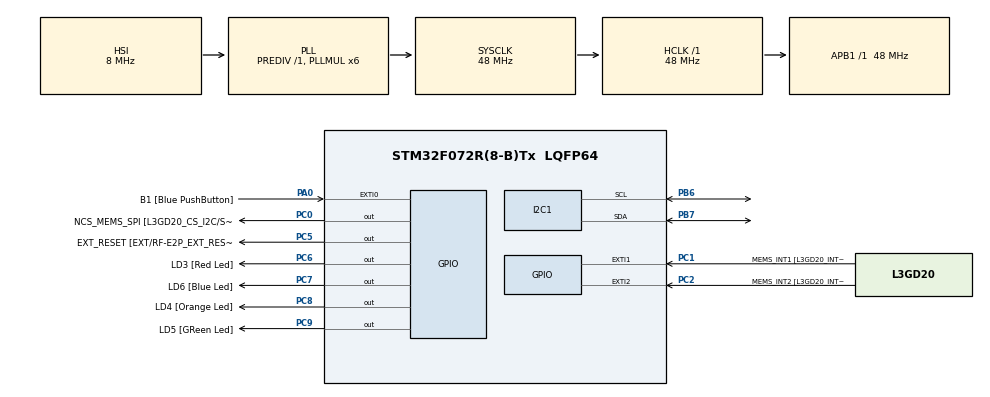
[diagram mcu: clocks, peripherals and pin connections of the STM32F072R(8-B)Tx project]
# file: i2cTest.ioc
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I2C1.Speed=100
I2C1.Timing=0x2000090E
Mcu.Family=STM32F0
Mcu.Name=STM32F072R(8-B)Tx
Mcu.Package=LQFP64
NVIC.TIM3_IRQn=true\:0\:0\:false\:false\:true
PA0.GPIO_Label=B1 [Blue PushButton]
PA0.GPIO_ModeDefaultEXTI=GPIO_MODE_EVT_RISING
PA0.Signal=GPXTI0
PA11.GPIO_Label=USBF4_DM
PA11.Signal=USB_DM
PA12.GPIO_Label=USBF4_DP
PA12.Signal=USB_DP
PA13.GPIO_Label=SWDIO
PA13.Signal=SYS_SWDIO
PA14.GPIO_Label=SWCLK
PA14.Signal=SYS_SWCLK
PA2.Signal=TSC_G1_IO3
PA3.Signal=TSC_G1_IO4
PA6.Signal=TSC_G2_IO3
PA7.Signal=TSC_G2_IO4
PB0.Signal=TSC_G3_IO2
PB1.Signal=TSC_G3_IO3
PB10.GPIO_Label=I2C2_SCL[EXT/RF-E2P_SCL]
PB10.Signal=I2C2_SCL
PB11.GPIO_Label=I2C2_SDA[EXT/RF-E2P_SDA]
PB11.Signal=I2C2_SDA
PB13.GPIO_Label=SPI2_SCK [L3GD20_SCL/SPC]
PB13.Signal=SPI2_SCK
PB14.GPIO_Label=SPI2_MISO [L3GD20_SDO]
PB14.Signal=SPI2_MISO
PB15.GPIO_Label=SPI2_MOSI [L3GD20_SDA/SDI]
PB15.Signal=SPI2_MOSI
PB6.Mode=I2C
PB6.Signal=I2C1_SCL
PB7.Mode=I2C
PB7.Signal=I2C1_SDA
PC0.GPIO_Label=NCS_MEMS_SPI [L3GD20_CS_I2C/SPI]
PC0.Signal=GPIO_Output
PC1.GPIO_Label=MEMS_INT1 [L3GD20_INT1]
PC1.GPIO_ModeDefaultEXTI=GPIO_MODE_EVT_RISING
PC1.Signal=GPXTI1
PC2.GPIO_Label=MEMS_INT2 [L3GD20_INT2]
PC2.GPIO_ModeDefaultEXTI=GPIO_MODE_EVT_RISING
PC2.Signal=GPXTI2
PC5.GPIO_Label=EXT_RESET [EXT/RF-E2P_EXT_RESET]
PC5.Signal=GPIO_Output
PC6.GPIO_Label=LD3 [Red Led]
PC6.Signal=GPIO_Output
PC7.GPIO_Label=LD6 [Blue Led]
PC7.Signal=GPIO_Output
PC8.GPIO_Label=LD4 [Orange Led]
PC8.Signal=GPIO_Output
PC9.GPIO_Label=LD5 [GReen Led]
PC9.Signal=GPIO_Output
ProjectManager.HeapSize=0x200
ProjectManager.StackSize=0x400
ProjectManager.TargetToolchain=SW4STM32
RCC.AHBFreq_Value=48000000
RCC.APB1Freq_Value=48000000
RCC.APB1TimFreq_Value=48000000
RCC.HCLKFreq_Value=48000000
RCC.PLLMUL=RCC_PLL_MUL6
RCC.SYSCLKFreq_VALUE=48000000
RCC.SYSCLKSource=RCC_SYSCLKSOURCE_PLLCLK
TIM3.Period=499
TIM3.Prescaler=48000
VP_TIM3_VS_ClockSourceINT.Mode=Internal
board=STM32F072B-DISCO

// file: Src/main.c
/**
  ******************************************************************************
  * File Name          : main.c
  * Description        : Main program body
  ******************************************************************************
  *
  * COPYRIGHT(c) 2016 STMicroelectronics
  *
  * Redistribution and use in source and binary forms, with or without modification,
  * are permitted provided that the following conditions are met:
  *   1. Redistributions of source code must retain the above copyright notice,
  *      this list of conditions and the following disclaimer.
  *   2. Redistributions in binary form must reproduce the above copyright notice,
  *      this list of conditions and the following disclaimer in the documentation
  *      and/or other materials provided with the distribution.
  *   3. Neither the name of STMicroelectronics nor the names of its contributors
  *      may be used to endorse or promote products derived from this software
  *      without specific prior written permission.
  *
  * THIS SOFTWARE IS PROVIDED BY THE COPYRIGHT HOLDERS AND CONTRIBUTORS "AS IS"
  * AND ANY EXPRESS OR IMPLIED WARRANTIES, INCLUDING, BUT NOT LIMITED TO, THE
  * IMPLIED WARRANTIES OF MERCHANTABILITY AND FITNESS FOR A PARTICULAR PURPOSE ARE
  * DISCLAIMED. IN NO EVENT SHALL THE COPYRIGHT HOLDER OR CONTRIBUTORS BE LIABLE
  * FOR ANY DIRECT, INDIRECT, INCIDENTAL, SPECIAL, EXEMPLARY, OR CONSEQUENTIAL
  * DAMAGES (INCLUDING, BUT NOT LIMITED TO, PROCUREMENT OF SUBSTITUTE GOODS OR
  * SERVICES; LOSS OF USE, DATA, OR PROFITS; OR BUSINESS INTERRUPTION) HOWEVER
  * CAUSED AND ON ANY THEORY OF LIABILITY, WHETHER IN CONTRACT, STRICT LIABILITY,
  * OR TORT (INCLUDING NEGLIGENCE OR OTHERWISE) ARISING IN ANY WAY OUT OF THE USE
  * OF THIS SOFTWARE, EVEN IF ADVISED OF THE POSSIBILITY OF SUCH DAMAGE.
  *
  ******************************************************************************
  */
#include "stm32f0xx_hal.h"
#include <stdio.h>
#include <stdlib.h>
//http://www.openstm32.org/tiki-view_forum_thread.php?comments_parentId=1904&forumId=7

I2C_HandleTypeDef hi2c1;

TIM_HandleTypeDef htim3;

/* USER CODE BEGIN PV */
/* Private variables ---------------------------------------------------------*/

/* USER CODE END PV */

void SystemClock_Config(void);
void Error_Handler(void);
static void MX_GPIO_Init(void);
static void MX_I2C1_Init(void);
static void MX_TIM3_Init(void);
/* USER CODE BEGIN PFP */
/* Private function prototypes -----------------------------------------------*/

/* USER CODE END PFP */

int main(void)
{

  /* USER CODE BEGIN 1 */

	I2C_GenerateSTART();
  /* USER CODE END 1 */

  /* MCU Configuration----------------------------------------------------------*/

  /* Reset of all peripherals, Initializes the Flash interface and the Systick. */
  HAL_Init();

  /* Configure the system clock */
  SystemClock_Config();

  /* Initialize all configured peripherals */
  MX_GPIO_Init();
  MX_I2C1_Init();
  MX_TIM3_Init();

  /* Infinite loop */
  /* USER CODE BEGIN WHILE */
  initialise_monitor_handles();

  printf("Hello !\n");
  int count;
  //setbuf(stdout,NULL);
  while (1)
  {
	  HAL_Delay(10000); //stop for 10sec
	  printf("intest\n");

  /* USER CODE END WHILE */

  }

}

/** System Clock Configuration
*/
void SystemClock_Config(void)
{

  RCC_OscInitTypeDef RCC_OscInitStruct;
  RCC_ClkInitTypeDef RCC_ClkInitStruct;
  RCC_PeriphCLKInitTypeDef PeriphClkInit;

  RCC_OscInitStruct.OscillatorType = RCC_OSCILLATORTYPE_HSI;
  RCC_OscInitStruct.HSIState = RCC_HSI_ON;
  RCC_OscInitStruct.HSICalibrationValue = 16;
  RCC_OscInitStruct.PLL.PLLState = RCC_PLL_ON;
  RCC_OscInitStruct.PLL.PLLSource = RCC_PLLSOURCE_HSI;
  RCC_OscInitStruct.PLL.PLLMUL = RCC_PLL_MUL6;
  RCC_OscInitStruct.PLL.PREDIV = RCC_PREDIV_DIV1;
  if (HAL_RCC_OscConfig(&RCC_OscInitStruct) != HAL_OK)
  {
    Error_Handler();
  }

  RCC_ClkInitStruct.ClockType = RCC_CLOCKTYPE_HCLK|RCC_CLOCKTYPE_SYSCLK
                              |RCC_CLOCKTYPE_PCLK1;
  RCC_ClkInitStruct.SYSCLKSource = RCC_SYSCLKSOURCE_PLLCLK;
  RCC_ClkInitStruct.AHBCLKDivider = RCC_SYSCLK_DIV1;
  RCC_ClkInitStruct.APB1CLKDivider = RCC_HCLK_DIV1;
  if (HAL_RCC_ClockConfig(&RCC_ClkInitStruct, FLASH_LATENCY_1) != HAL_OK)
  {
    Error_Handler();
  }

  PeriphClkInit.PeriphClockSelection = RCC_PERIPHCLK_I2C1;
  PeriphClkInit.I2c1ClockSelection = RCC_I2C1CLKSOURCE_HSI;
  if (HAL_RCCEx_PeriphCLKConfig(&PeriphClkInit) != HAL_OK)
  {
    Error_Handler();
  }

  HAL_SYSTICK_Config(HAL_RCC_GetHCLKFreq()/1000);

  HAL_SYSTICK_CLKSourceConfig(SYSTICK_CLKSOURCE_HCLK);

  /* SysTick_IRQn interrupt configuration */
  HAL_NVIC_SetPriority(SysTick_IRQn, 0, 0);
}

/* I2C1 init function */
static void MX_I2C1_Init(void)
{

  hi2c1.Instance = I2C1;
  hi2c1.Init.Timing = 0x2000090E;
  hi2c1.Init.OwnAddress1 = 0;
  hi2c1.Init.AddressingMode = I2C_ADDRESSINGMODE_7BIT;
  hi2c1.Init.DualAddressMode = I2C_DUALADDRESS_DISABLE;
  hi2c1.Init.OwnAddress2 = 0;
  hi2c1.Init.OwnAddress2Masks = I2C_OA2_NOMASK;
  hi2c1.Init.GeneralCallMode = I2C_GENERALCALL_DISABLE;
  hi2c1.Init.NoStretchMode = I2C_NOSTRETCH_DISABLE;
  if (HAL_I2C_Init(&hi2c1) != HAL_OK)
  {
    Error_Handler();
  }

    /**Configure Analogue filter
    */
  if (HAL_I2CEx_ConfigAnalogFilter(&hi2c1, I2C_ANALOGFILTER_ENABLE) != HAL_OK)
  {
    Error_Handler();
  }

}

/* TIM3 init function */
static void MX_TIM3_Init(void)
{

  TIM_ClockConfigTypeDef sClockSourceConfig;
  TIM_MasterConfigTypeDef sMasterConfig;

  htim3.Instance = TIM3;
  htim3.Init.Prescaler = 48000;
  htim3.Init.CounterMode = TIM_COUNTERMODE_UP;
  htim3.Init.Period = 499;
  htim3.Init.ClockDivision = TIM_CLOCKDIVISION_DIV1;
  if (HAL_TIM_Base_Init(&htim3) != HAL_OK)
  {
    Error_Handler();
  }

  sClockSourceConfig.ClockSource = TIM_CLOCKSOURCE_INTERNAL;
  if (HAL_TIM_ConfigClockSource(&htim3, &sClockSourceConfig) != HAL_OK)
  {
    Error_Handler();
  }

  sMasterConfig.MasterOutputTrigger = TIM_TRGO_RESET;
  sMasterConfig.MasterSlaveMode = TIM_MASTERSLAVEMODE_DISABLE;
  if (HAL_TIMEx_MasterConfigSynchronization(&htim3, &sMasterConfig) != HAL_OK)
  {
    Error_Handler();
  }

}

/** Configure pins as
        * Analog
        * Input
        * Output
        * EVENT_OUT
        * EXTI
     PA2   ------> TSC_G1_IO3
     PA3   ------> TSC_G1_IO4
     PA6   ------> TSC_G2_IO3
     PA7   ------> TSC_G2_IO4
     PB0   ------> TSC_G3_IO2
     PB1   ------> TSC_G3_IO3
     PB10   ------> I2C2_SCL
     PB11   ------> I2C2_SDA
     PB13   ------> SPI2_SCK
     PB14   ------> SPI2_MISO
     PB15   ------> SPI2_MOSI
*/
static void MX_GPIO_Init(void)
{

  GPIO_InitTypeDef GPIO_InitStruct;

  /* GPIO Ports Clock Enable */
  __HAL_RCC_GPIOC_CLK_ENABLE();
  __HAL_RCC_GPIOA_CLK_ENABLE();
  __HAL_RCC_GPIOB_CLK_ENABLE();

  /*Configure GPIO pin Output Level */
  HAL_GPIO_WritePin(GPIOC, NCS_MEMS_SPI_Pin|EXT_RESET_Pin|LD3_Pin|LD6_Pin
                          |LD4_Pin|LD5_Pin, GPIO_PIN_RESET);

  /*Configure GPIO pins : NCS_MEMS_SPI_Pin EXT_RESET_Pin LD3_Pin LD6_Pin
                           LD4_Pin LD5_Pin */
  GPIO_InitStruct.Pin = NCS_MEMS_SPI_Pin|EXT_RESET_Pin|LD3_Pin|LD6_Pin
                          |LD4_Pin|LD5_Pin;
  GPIO_InitStruct.Mode = GPIO_MODE_OUTPUT_PP;
  GPIO_InitStruct.Pull = GPIO_NOPULL;
  GPIO_InitStruct.Speed = GPIO_SPEED_FREQ_LOW;
  HAL_GPIO_Init(GPIOC, &GPIO_InitStruct);

  /*Configure GPIO pins : MEMS_INT1_Pin MEMS_INT2_Pin */
  GPIO_InitStruct.Pin = MEMS_INT1_Pin|MEMS_INT2_Pin;
  GPIO_InitStruct.Mode = GPIO_MODE_EVT_RISING;
  GPIO_InitStruct.Pull = GPIO_NOPULL;
  HAL_GPIO_Init(GPIOC, &GPIO_InitStruct);

  /*Configure GPIO pin : B1_Pin */
  GPIO_InitStruct.Pin = B1_Pin;
  GPIO_InitStruct.Mode = GPIO_MODE_EVT_RISING;
  GPIO_InitStruct.Pull = GPIO_NOPULL;
  HAL_GPIO_Init(B1_GPIO_Port, &GPIO_InitStruct);

  /*Configure GPIO pins : PA2 PA3 PA6 PA7 */
  GPIO_InitStruct.Pin = GPIO_PIN_2|GPIO_PIN_3|GPIO_PIN_6|GPIO_PIN_7;
  GPIO_InitStruct.Mode = GPIO_MODE_AF_PP;
  GPIO_InitStruct.Pull = GPIO_NOPULL;
  GPIO_InitStruct.Speed = GPIO_SPEED_FREQ_LOW;
  GPIO_InitStruct.Alternate = GPIO_AF3_TSC;
  HAL_GPIO_Init(GPIOA, &GPIO_InitStruct);

  /*Configure GPIO pins : PB0 PB1 */
  GPIO_InitStruct.Pin = GPIO_PIN_0|GPIO_PIN_1;
  GPIO_InitStruct.Mode = GPIO_MODE_AF_PP;
  GPIO_InitStruct.Pull = GPIO_NOPULL;
  GPIO_InitStruct.Speed = GPIO_SPEED_FREQ_LOW;
  GPIO_InitStruct.Alternate = GPIO_AF3_TSC;
  HAL_GPIO_Init(GPIOB, &GPIO_InitStruct);

  /*Configure GPIO pins : PB10 PB11 */
  GPIO_InitStruct.Pin = GPIO_PIN_10|GPIO_PIN_11;
  GPIO_InitStruct.Mode = GPIO_MODE_AF_OD;
  GPIO_InitStruct.Pull = GPIO_PULLUP;
  GPIO_InitStruct.Speed = GPIO_SPEED_FREQ_HIGH;
  GPIO_InitStruct.Alternate = GPIO_AF1_I2C2;
  HAL_GPIO_Init(GPIOB, &GPIO_InitStruct);

  /*Configure GPIO pins : PB13 PB14 PB15 */
  GPIO_InitStruct.Pin = GPIO_PIN_13|GPIO_PIN_14|GPIO_PIN_15;
  GPIO_InitStruct.Mode = GPIO_MODE_AF_PP;
  GPIO_InitStruct.Pull = GPIO_NOPULL;
  GPIO_InitStruct.Speed = GPIO_SPEED_FREQ_HIGH;
  GPIO_InitStruct.Alternate = GPIO_AF0_SPI2;
  HAL_GPIO_Init(GPIOB, &GPIO_InitStruct);

}

void Error_Handler(void)
{
  while(1)
  {
  }
}

/************************ (C) COPYRIGHT STMicroelectronics *****END OF FILE****/
